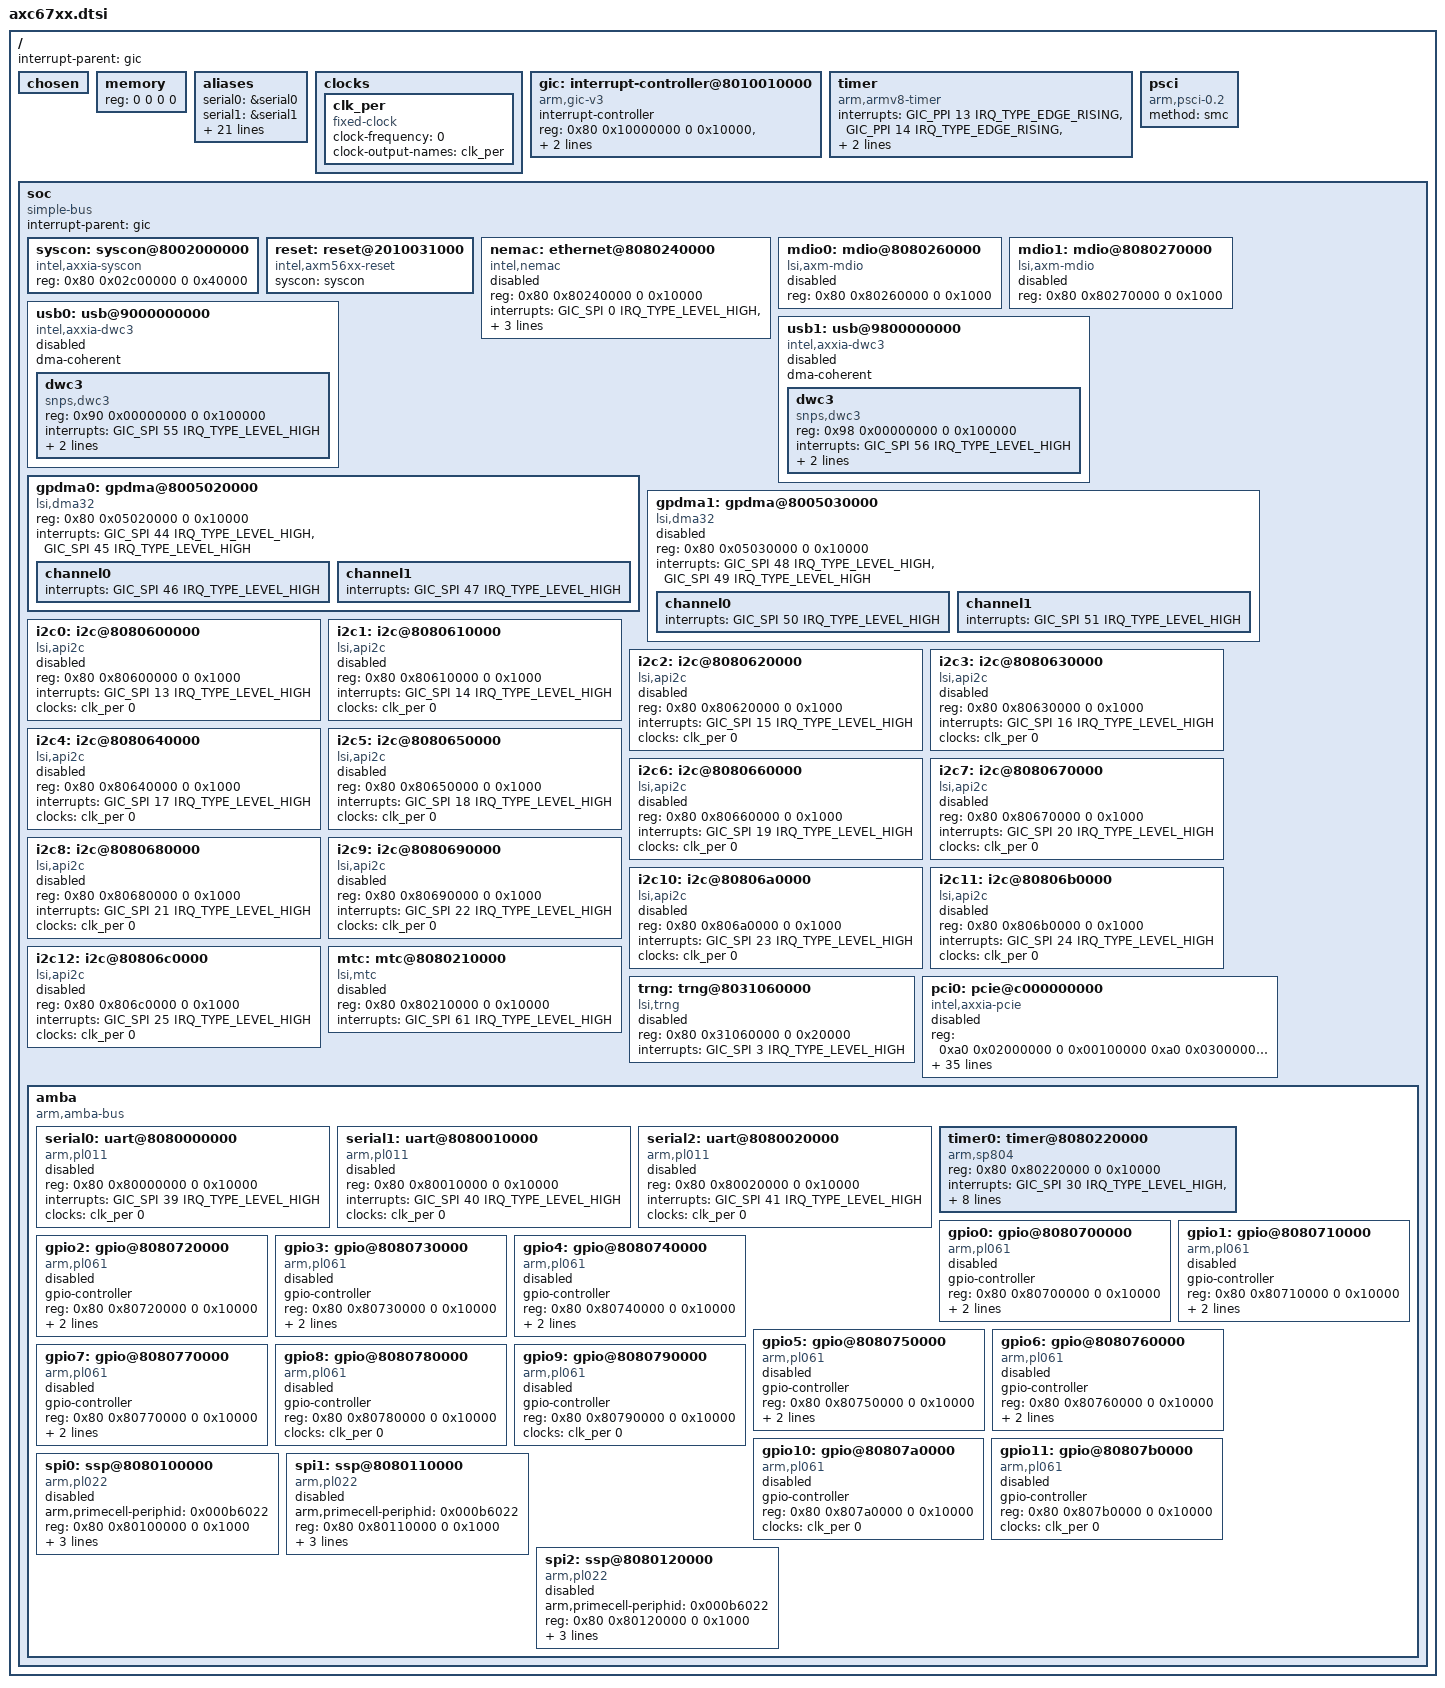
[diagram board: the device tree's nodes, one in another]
/*
 * arch/arm64/boot/dts/intel/axc67xx.dtsi
 *
 * Copyright (C) 2015 Intel Corp.
 *
 * This program is free software; you can redistribute it and/or modify
 * it under the terms of the GNU General Public License as published by
 * the Free Software Foundation; either version 2 of the License, or
 * (at your option) any later version.
 */

#include <dt-bindings/interrupt-controller/arm-gic.h>

/ {
	#address-cells = <2>;
	#size-cells = <2>;

	interrupt-parent = <&gic>;

	chosen {
	};

	memory {
		device_type = "memory";
		reg = <0 0 0 0>;
	};

	aliases {
		serial0	  = &serial0;
		serial1   = &serial1;
		serial2	  = &serial2;
		timer	  = &timer0;
		ethernet0 = &nemac;
		i2c0	  = &i2c0;
		i2c1	  = &i2c1;
		i2c2	  = &i2c2;
		i2c3	  = &i2c3;
		i2c4	  = &i2c4;
		i2c5	  = &i2c5;
		i2c6	  = &i2c6;
		i2c7	  = &i2c7;
		i2c8	  = &i2c8;
		i2c9	  = &i2c9;
		i2c10	  = &i2c10;
		i2c11	  = &i2c11;
		i2c12	  = &i2c12;
		spi0	  = &spi0;
		spi1	  = &spi1;
		spi2	  = &spi2;
		gpdma0	  = &gpdma0;
		gpdma1	  = &gpdma1;
	};

	clocks {
		#address-cells = <1>;
		#size-cells = <0>;

		clk_per: clk_per {
			compatible = "fixed-clock";
			#clock-cells = <0>;
			clock-frequency = <0>; /* Set by the Boot Loader */
			clock-output-names = "clk_per";
		};
	};

	gic: interrupt-controller@8010010000 {
		compatible = "arm,gic-v3";
		#interrupt-cells = <3>;
		#address-cells = <0>;
		interrupt-controller;
		reg = <0x80 0x10000000 0 0x10000>,
		      <0x80 0x10400000 0 0x400000>;
		interrupts = <GIC_PPI 9 IRQ_TYPE_LEVEL_HIGH>;
	};

	timer {
		compatible = "arm,armv8-timer";
		interrupts = <GIC_PPI 13 IRQ_TYPE_EDGE_RISING>,
			     <GIC_PPI 14 IRQ_TYPE_EDGE_RISING>,
			     <GIC_PPI 11 IRQ_TYPE_EDGE_RISING>,
			     <GIC_PPI 10 IRQ_TYPE_EDGE_RISING>;
	};

	psci {
		compatible      = "arm,psci-0.2";
		method          = "smc";
	};

	soc {
		compatible = "simple-bus";
		device_type = "soc";
		#address-cells = <2>;
		#size-cells = <2>;
		interrupt-parent = <&gic>;
		ranges;

		syscon: syscon@8002000000 {
			compatible = "intel,axxia-syscon", "syscon";
			reg = <0x80 0x02c00000 0 0x40000>;
		};

		reset: reset@2010031000 {
			compatible = "intel,axm56xx-reset";
			syscon = <&syscon>;
		};

		nemac: ethernet@8080240000 {
			compatible = "intel,nemac";
			reg = <0x80 0x80240000 0 0x10000>;
			interrupts = <GIC_SPI 0 IRQ_TYPE_LEVEL_HIGH>,
				     <GIC_SPI 1 IRQ_TYPE_LEVEL_HIGH>;
			dma-coherent;
			mac-address = [00 00 00 00 00 00];
			status = "disabled";
		};

		mdio0: mdio@8080260000 {
			compatible = "lsi,axm-mdio";
			#address-cells = <1>;
			#size-cells = <0>;
			reg = <0x80 0x80260000 0 0x1000>;
			status = "disabled";
		};

		mdio1: mdio@8080270000 {
			compatible = "lsi,axm-mdio";
			#address-cells = <1>;
			#size-cells = <0>;
			reg = <0x80 0x80270000 0 0x1000>;
			status = "disabled";
		};

		usb0: usb@9000000000 {
			compatible = "intel,axxia-dwc3";
			dma-coherent;
			status = "disabled";
			#address-cells = <2>;
			#size-cells = <2>;
			ranges;
			dwc3 {
				compatible = "snps,dwc3";
				reg = <0x90 0x00000000 0 0x100000>;
				interrupts = <GIC_SPI 55 IRQ_TYPE_LEVEL_HIGH>;
				snps,axxia_usb_944754_quirk;
				snps,axxia_usb_952264_quirk;
			};
		};

		usb1: usb@9800000000 {
			compatible = "intel,axxia-dwc3";
			dma-coherent;
			status = "disabled";
			#address-cells = <2>;
			#size-cells = <2>;
			ranges;
			dwc3 {
				compatible = "snps,dwc3";
				reg = <0x98 0x00000000 0 0x100000>;
				interrupts = <GIC_SPI 56 IRQ_TYPE_LEVEL_HIGH>;
				snps,axxia_usb_944754_quirk;
				snps,axxia_usb_952264_quirk;
			};
		};

		gpdma0: gpdma@8005020000 {
			compatible = "lsi,dma32";
			reg = <0x80 0x05020000 0 0x10000>;
			interrupts = <GIC_SPI 44 IRQ_TYPE_LEVEL_HIGH>,
					<GIC_SPI 45 IRQ_TYPE_LEVEL_HIGH>;
			channel0 {
				interrupts = <GIC_SPI 46 IRQ_TYPE_LEVEL_HIGH>;
			};

			channel1 {
				interrupts = <GIC_SPI 47 IRQ_TYPE_LEVEL_HIGH>;
			};
		};

		gpdma1: gpdma@8005030000 {
			compatible = "lsi,dma32";
			reg = <0x80 0x05030000 0 0x10000>;
			interrupts = <GIC_SPI 48 IRQ_TYPE_LEVEL_HIGH>,
					<GIC_SPI 49 IRQ_TYPE_LEVEL_HIGH>;
			status = "disabled";
			channel0 {
				interrupts = <GIC_SPI 50 IRQ_TYPE_LEVEL_HIGH>;
			};

			channel1 {
				interrupts = <GIC_SPI 51 IRQ_TYPE_LEVEL_HIGH>;
			};
		};

		i2c0: i2c@8080600000 {
			compatible = "lsi,api2c";
			#address-cells = <1>;
			#size-cells = <0>;
			reg = <0x80 0x80600000 0 0x1000>;
			interrupts = <GIC_SPI 13 IRQ_TYPE_LEVEL_HIGH>;
			clocks = <&clk_per 0>;
			clock-names = "i2c";
			status = "disabled";
		};

		i2c1: i2c@8080610000 {
			compatible = "lsi,api2c";
			#address-cells = <1>;
			#size-cells = <0>;
			reg = <0x80 0x80610000 0 0x1000>;
			interrupts = <GIC_SPI 14 IRQ_TYPE_LEVEL_HIGH>;
			clocks = <&clk_per 0>;
			clock-names = "i2c";
			status = "disabled";
		};

		i2c2: i2c@8080620000 {
			compatible = "lsi,api2c";
			#address-cells = <1>;
			#size-cells = <0>;
			reg = <0x80 0x80620000 0 0x1000>;
			interrupts = <GIC_SPI 15 IRQ_TYPE_LEVEL_HIGH>;
			clocks = <&clk_per 0>;
			clock-names = "i2c";
			status = "disabled";
		};

		i2c3: i2c@8080630000 {
			compatible = "lsi,api2c";
			#address-cells = <1>;
			#size-cells = <0>;
			reg = <0x80 0x80630000 0 0x1000>;
			interrupts = <GIC_SPI 16 IRQ_TYPE_LEVEL_HIGH>;
			clocks = <&clk_per 0>;
			clock-names = "i2c";
			status = "disabled";
		};

		i2c4: i2c@8080640000 {
			compatible = "lsi,api2c";
			#address-cells = <1>;
			#size-cells = <0>;
			reg = <0x80 0x80640000 0 0x1000>;
			interrupts = <GIC_SPI 17 IRQ_TYPE_LEVEL_HIGH>;
			clocks = <&clk_per 0>;
			clock-names = "i2c";
			status = "disabled";
		};

		i2c5: i2c@8080650000 {
			compatible = "lsi,api2c";
			#address-cells = <1>;
			#size-cells = <0>;
			reg = <0x80 0x80650000 0 0x1000>;
			interrupts = <GIC_SPI 18 IRQ_TYPE_LEVEL_HIGH>;
			clocks = <&clk_per 0>;
			clock-names = "i2c";
			status = "disabled";
		};

		i2c6: i2c@8080660000 {
			compatible = "lsi,api2c";
			#address-cells = <1>;
			#size-cells = <0>;
			reg = <0x80 0x80660000 0 0x1000>;
			interrupts = <GIC_SPI 19 IRQ_TYPE_LEVEL_HIGH>;
			clocks = <&clk_per 0>;
			clock-names = "i2c";
			status = "disabled";
		};

		i2c7: i2c@8080670000 {
			compatible = "lsi,api2c";
			#address-cells = <1>;
			#size-cells = <0>;
			reg = <0x80 0x80670000 0 0x1000>;
			interrupts = <GIC_SPI 20 IRQ_TYPE_LEVEL_HIGH>;
			clocks = <&clk_per 0>;
			clock-names = "i2c";
			status = "disabled";
		};

		i2c8: i2c@8080680000 {
			compatible = "lsi,api2c";
			#address-cells = <1>;
			#size-cells = <0>;
			reg = <0x80 0x80680000 0 0x1000>;
			interrupts = <GIC_SPI 21 IRQ_TYPE_LEVEL_HIGH>;
			clocks = <&clk_per 0>;
			clock-names = "i2c";
			status = "disabled";
		};

		i2c9: i2c@8080690000 {
			compatible = "lsi,api2c";
			#address-cells = <1>;
			#size-cells = <0>;
			reg = <0x80 0x80690000 0 0x1000>;
			interrupts = <GIC_SPI 22 IRQ_TYPE_LEVEL_HIGH>;
			clocks = <&clk_per 0>;
			clock-names = "i2c";
			status = "disabled";
		};

		i2c10: i2c@80806a0000 {
			compatible = "lsi,api2c";
			#address-cells = <1>;
			#size-cells = <0>;
			reg = <0x80 0x806a0000 0 0x1000>;
			interrupts = <GIC_SPI 23 IRQ_TYPE_LEVEL_HIGH>;
			clocks = <&clk_per 0>;
			clock-names = "i2c";
			status = "disabled";
		};

		i2c11: i2c@80806b0000 {
			compatible = "lsi,api2c";
			#address-cells = <1>;
			#size-cells = <0>;
			reg = <0x80 0x806b0000 0 0x1000>;
			interrupts = <GIC_SPI 24 IRQ_TYPE_LEVEL_HIGH>;
			clocks = <&clk_per 0>;
			clock-names = "i2c";
			status = "disabled";
		};

		i2c12: i2c@80806c0000 {
			compatible = "lsi,api2c";
			#address-cells = <1>;
			#size-cells = <0>;
			reg = <0x80 0x806c0000 0 0x1000>;
			interrupts = <GIC_SPI 25 IRQ_TYPE_LEVEL_HIGH>;
			clocks = <&clk_per 0>;
			clock-names = "i2c";
			status = "disabled";
		};

		mtc: mtc@8080210000 {
			compatible = "lsi,mtc";
			reg = <0x80 0x80210000 0 0x10000>;
			interrupts = <GIC_SPI 61 IRQ_TYPE_LEVEL_HIGH>;
			status = "disabled";
		};

		trng: trng@8031060000 {
			compatible = "lsi,trng";
			reg = <0x80 0x31060000 0 0x20000>;
			interrupts = <GIC_SPI 3 IRQ_TYPE_LEVEL_HIGH>;
			status = "disabled";
		};

		pci0: pcie@c000000000 {
			compatible = "intel,axxia-pcie";
			device_type = "pci";
			reg = <0xa0 0x02000000 0 0x00100000   /* dbi */
			       0xa0 0x03000000 0 0x00008000   /* AXI gpreg */
			       0xa0 0x03008000 0 0x00008000>; /* CC gpreg */
			reg-names = "dbi", "axi_gpreg", "cc_gpreg";
			#interrupt-cells = <1>;
			#address-cells = <3>;
			#size-cells = <2>;
			num-lanes = <1>;
			ranges = <0x00000000 0x000000c0 0x40000000
				0xc0 0x40000000
				0x00 0x10000000         /* config space */
				0x03000000 0x00000000 0xa0000000
				0xc0 0x00000000
				0x00 0x40000000>;       /* outbound mem */
			interrupts = <GIC_SPI 91 IRQ_TYPE_LEVEL_HIGH>,
				<GIC_SPI 94 IRQ_TYPE_LEVEL_HIGH>,
				<GIC_SPI 97 IRQ_TYPE_LEVEL_HIGH>,
				<GIC_SPI 98 IRQ_TYPE_LEVEL_HIGH>,
				<GIC_SPI 99 IRQ_TYPE_LEVEL_HIGH>,
				<GIC_SPI 100 IRQ_TYPE_LEVEL_HIGH>,
				<GIC_SPI 101 IRQ_TYPE_LEVEL_HIGH>,
				<GIC_SPI 102 IRQ_TYPE_LEVEL_HIGH>,
				<GIC_SPI 103 IRQ_TYPE_LEVEL_HIGH>,
				<GIC_SPI 104 IRQ_TYPE_LEVEL_HIGH>,
				<GIC_SPI 105 IRQ_TYPE_LEVEL_HIGH>,
				<GIC_SPI 106 IRQ_TYPE_LEVEL_HIGH>,
				<GIC_SPI 107 IRQ_TYPE_LEVEL_HIGH>,
				<GIC_SPI 108 IRQ_TYPE_LEVEL_HIGH>,
				<GIC_SPI 109 IRQ_TYPE_LEVEL_HIGH>,
				<GIC_SPI 110 IRQ_TYPE_LEVEL_HIGH>,
				<GIC_SPI 111 IRQ_TYPE_LEVEL_HIGH>,
				<GIC_SPI 112 IRQ_TYPE_LEVEL_HIGH>,
				<GIC_SPI 113 IRQ_TYPE_LEVEL_HIGH>,
				<GIC_SPI 114 IRQ_TYPE_LEVEL_HIGH>,
				<GIC_SPI 115 IRQ_TYPE_LEVEL_HIGH>,
				<GIC_SPI 116 IRQ_TYPE_LEVEL_HIGH>,
				<GIC_SPI 117 IRQ_TYPE_LEVEL_HIGH>,
				<GIC_SPI 118 IRQ_TYPE_LEVEL_HIGH>,
				<GIC_SPI 119 IRQ_TYPE_LEVEL_HIGH>,
				<GIC_SPI 120 IRQ_TYPE_LEVEL_HIGH>,
				<GIC_SPI 121 IRQ_TYPE_LEVEL_HIGH>,
				<GIC_SPI 122 IRQ_TYPE_LEVEL_HIGH>,
				<GIC_SPI 123 IRQ_TYPE_LEVEL_HIGH>,
				<GIC_SPI 124 IRQ_TYPE_LEVEL_HIGH>,
				<GIC_SPI 125 IRQ_TYPE_LEVEL_HIGH>,
				<GIC_SPI 126 IRQ_TYPE_LEVEL_HIGH>,
				<GIC_SPI 127 IRQ_TYPE_LEVEL_HIGH>,
				<GIC_SPI 128 IRQ_TYPE_LEVEL_HIGH>;
			status = "disabled";
		};

		amba {
			compatible = "arm,amba-bus";
			#address-cells = <2>;
			#size-cells = <2>;
			ranges;

			serial0: uart@8080000000 {
				compatible = "arm,pl011", "arm,primecell";
				reg = <0x80 0x80000000 0 0x10000>;
				interrupts = <GIC_SPI 39 IRQ_TYPE_LEVEL_HIGH>;
				clocks = <&clk_per 0>;
				clock-names = "apb_pclk";
				status = "disabled";
			};

			serial1: uart@8080010000 {
				compatible = "arm,pl011", "arm,primecell";
				reg = <0x80 0x80010000 0 0x10000>;
				interrupts = <GIC_SPI 40 IRQ_TYPE_LEVEL_HIGH>;
				clocks = <&clk_per 0>;
				clock-names = "apb_pclk";
				status = "disabled";
			};

			serial2: uart@8080020000 {
				compatible = "arm,pl011", "arm,primecell";
				reg = <0x80 0x80020000 0 0x10000>;
				interrupts = <GIC_SPI 41 IRQ_TYPE_LEVEL_HIGH>;
				clocks = <&clk_per 0>;
				clock-names = "apb_pclk";
				status = "disabled";
			};

			timer0: timer@8080220000 {
				compatible = "arm,sp804", "arm,primecell";
				reg = <0x80 0x80220000 0 0x10000>;
				interrupts = <GIC_SPI 30 IRQ_TYPE_LEVEL_HIGH>,
					     <GIC_SPI 31 IRQ_TYPE_LEVEL_HIGH>,
					     <GIC_SPI 32 IRQ_TYPE_LEVEL_HIGH>,
					     <GIC_SPI 33 IRQ_TYPE_LEVEL_HIGH>,
					     <GIC_SPI 34 IRQ_TYPE_LEVEL_HIGH>,
					     <GIC_SPI 35 IRQ_TYPE_LEVEL_HIGH>,
					     <GIC_SPI 36 IRQ_TYPE_LEVEL_HIGH>,
					     <GIC_SPI 37 IRQ_TYPE_LEVEL_HIGH>;
				clocks = <&clk_per 0>;
				clock-names = "apb_pclk";
			};

			gpio0: gpio@8080700000 {
				#gpio-cells = <2>;
				compatible = "arm,pl061", "arm,primecell";
				gpio-controller;
				reg = <0x80 0x80700000 0 0x10000>;
				interrupts = <GIC_SPI 5 IRQ_TYPE_LEVEL_HIGH>;
				clocks = <&clk_per 0>;
				clock-names = "apb_pclk";
				status = "disabled";
			};

			gpio1: gpio@8080710000 {
				#gpio-cells = <2>;
				compatible = "arm,pl061", "arm,primecell";
				gpio-controller;
				reg = <0x80 0x80710000 0 0x10000>;
				interrupts = <GIC_SPI 6 IRQ_TYPE_LEVEL_HIGH>;
				clocks = <&clk_per 0>;
				clock-names = "apb_pclk";
				status = "disabled";
			};

			gpio2: gpio@8080720000 {
				#gpio-cells = <2>;
				compatible = "arm,pl061", "arm,primecell";
				gpio-controller;
				reg = <0x80 0x80720000 0 0x10000>;
				interrupts = <GIC_SPI 7 IRQ_TYPE_LEVEL_HIGH>;
				clocks = <&clk_per 0>;
				clock-names = "apb_pclk";
				status = "disabled";
			};

			gpio3: gpio@8080730000 {
				#gpio-cells = <2>;
				compatible = "arm,pl061", "arm,primecell";
				gpio-controller;
				reg = <0x80 0x80730000 0 0x10000>;
				interrupts = <GIC_SPI 8 IRQ_TYPE_LEVEL_HIGH>;
				clocks = <&clk_per 0>;
				clock-names = "apb_pclk";
				status = "disabled";
			};

			gpio4: gpio@8080740000 {
				#gpio-cells = <2>;
				compatible = "arm,pl061", "arm,primecell";
				gpio-controller;
				reg = <0x80 0x80740000 0 0x10000>;
				interrupts = <GIC_SPI 9 IRQ_TYPE_LEVEL_HIGH>;
				clocks = <&clk_per 0>;
				clock-names = "apb_pclk";
				status = "disabled";
			};

			gpio5: gpio@8080750000 {
				#gpio-cells = <2>;
				compatible = "arm,pl061", "arm,primecell";
				gpio-controller;
				reg = <0x80 0x80750000 0 0x10000>;
				interrupts = <GIC_SPI 10 IRQ_TYPE_LEVEL_HIGH>;
				clocks = <&clk_per 0>;
				clock-names = "apb_pclk";
				status = "disabled";
			};

			gpio6: gpio@8080760000 {
				#gpio-cells = <2>;
				compatible = "arm,pl061", "arm,primecell";
				gpio-controller;
				reg = <0x80 0x80760000 0 0x10000>;
				interrupts = <GIC_SPI 11 IRQ_TYPE_LEVEL_HIGH>;
				clocks = <&clk_per 0>;
				clock-names = "apb_pclk";
				status = "disabled";
			};

			gpio7: gpio@8080770000 {
				#gpio-cells = <2>;
				compatible = "arm,pl061", "arm,primecell";
				gpio-controller;
				reg = <0x80 0x80770000 0 0x10000>;
				interrupts = <GIC_SPI 12 IRQ_TYPE_LEVEL_HIGH>;
				clocks = <&clk_per 0>;
				clock-names = "apb_pclk";
				status = "disabled";
			};

			gpio8: gpio@8080780000 {
				#gpio-cells = <2>;
				compatible = "arm,pl061", "arm,primecell";
				gpio-controller;
				reg = <0x80 0x80780000 0 0x10000>;
				clocks = <&clk_per 0>;
				clock-names = "apb_pclk";
				status = "disabled";
			};

			gpio9: gpio@8080790000 {
				#gpio-cells = <2>;
				compatible = "arm,pl061", "arm,primecell";
				gpio-controller;
				reg = <0x80 0x80790000 0 0x10000>;
				clocks = <&clk_per 0>;
				clock-names = "apb_pclk";
				status = "disabled";
			};

			gpio10: gpio@80807a0000 {
				#gpio-cells = <2>;
				compatible = "arm,pl061", "arm,primecell";
				gpio-controller;
				reg = <0x80 0x807a0000 0 0x10000>;
				clocks = <&clk_per 0>;
				clock-names = "apb_pclk";
				status = "disabled";
			};

			gpio11: gpio@80807b0000 {
				#gpio-cells = <2>;
				compatible = "arm,pl061", "arm,primecell";
				gpio-controller;
				reg = <0x80 0x807b0000 0 0x10000>;
				clocks = <&clk_per 0>;
				clock-names = "apb_pclk";
				status = "disabled";
			};

			spi0: ssp@8080100000 {
				compatible = "arm,pl022", "arm,primecell";
				arm,primecell-periphid = <0x000b6022>;
				#address-cells = <1>;
				#size-cells = <0>;
				reg = <0x80 0x80100000 0 0x1000>;
				interrupts = <GIC_SPI 26 IRQ_TYPE_LEVEL_HIGH>;
				num-cs = <5>;
				clocks = <&clk_per 0>;
				clock-names = "apb_pclk";
				status = "disabled";
			};

			spi1: ssp@8080110000 {
				compatible = "arm,pl022", "arm,primecell";
				arm,primecell-periphid = <0x000b6022>;
				#address-cells = <1>;
				#size-cells = <0>;
				reg = <0x80 0x80110000 0 0x1000>;
				interrupts = <GIC_SPI 27 IRQ_TYPE_LEVEL_HIGH>;
				num-cs = <5>;
				clocks = <&clk_per 0>;
				clock-names = "apb_pclk";
				status = "disabled";
			};

			spi2: ssp@8080120000 {
				compatible = "arm,pl022", "arm,primecell";
				arm,primecell-periphid = <0x000b6022>;
				#address-cells = <1>;
				#size-cells = <0>;
				reg = <0x80 0x80120000 0 0x1000>;
				interrupts = <GIC_SPI 28 IRQ_TYPE_LEVEL_HIGH>;
				num-cs = <5>;
				clocks = <&clk_per 0>;
				clock-names = "apb_pclk";
				status = "disabled";
			};
		};
	};
};

/*
  Local Variables:
  mode: C
  End:
*/
